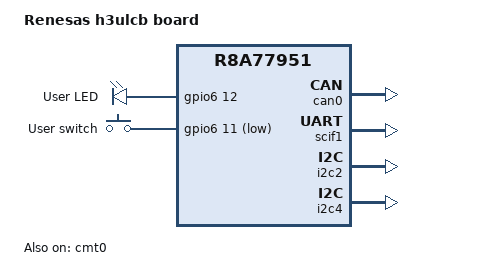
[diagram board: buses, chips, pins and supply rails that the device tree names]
/*
 * Copyright (c) 2021 IoT.bzh
 *
 * SPDX-License-Identifier: Apache-2.0
 *
 */

/dts-v1/;
#include <arm/renesas/gen3/r8a77951.dtsi>

/ {
	model = "Renesas h3ulcb board";
	compatible = "renesas,h3ulcb-cr7";

	chosen {
		zephyr,sram = &sram0;
		zephyr,console = &scif1;
		zephyr,shell-uart = &scif1;
		zephyr,canbus = &can0;
	};

	leds {
		compatible = "gpio-leds";
		user_led: led_5 {
			gpios = <&gpio6 12 GPIO_ACTIVE_HIGH>;
			label = "User LED";
		};
	};

	gpio_keys {
		compatible = "gpio-keys";
		user_button: sw3 {
			gpios = <&gpio6 11 GPIO_ACTIVE_LOW>;
			label = "User switch";
		};
	};

	aliases {
		led0 = &user_led;
		sw0 = &user_button;
	};
};

&cmt0 {
	status = "okay";
	clock-frequency = <32000>;
};

&gpio6 {
	status = "okay";
};

&can0 {
	status = "okay";
};

&scif1 {
	status = "okay";
};

&i2c2 {
	status = "okay";
};

&i2c4 {
	status = "okay";
};
